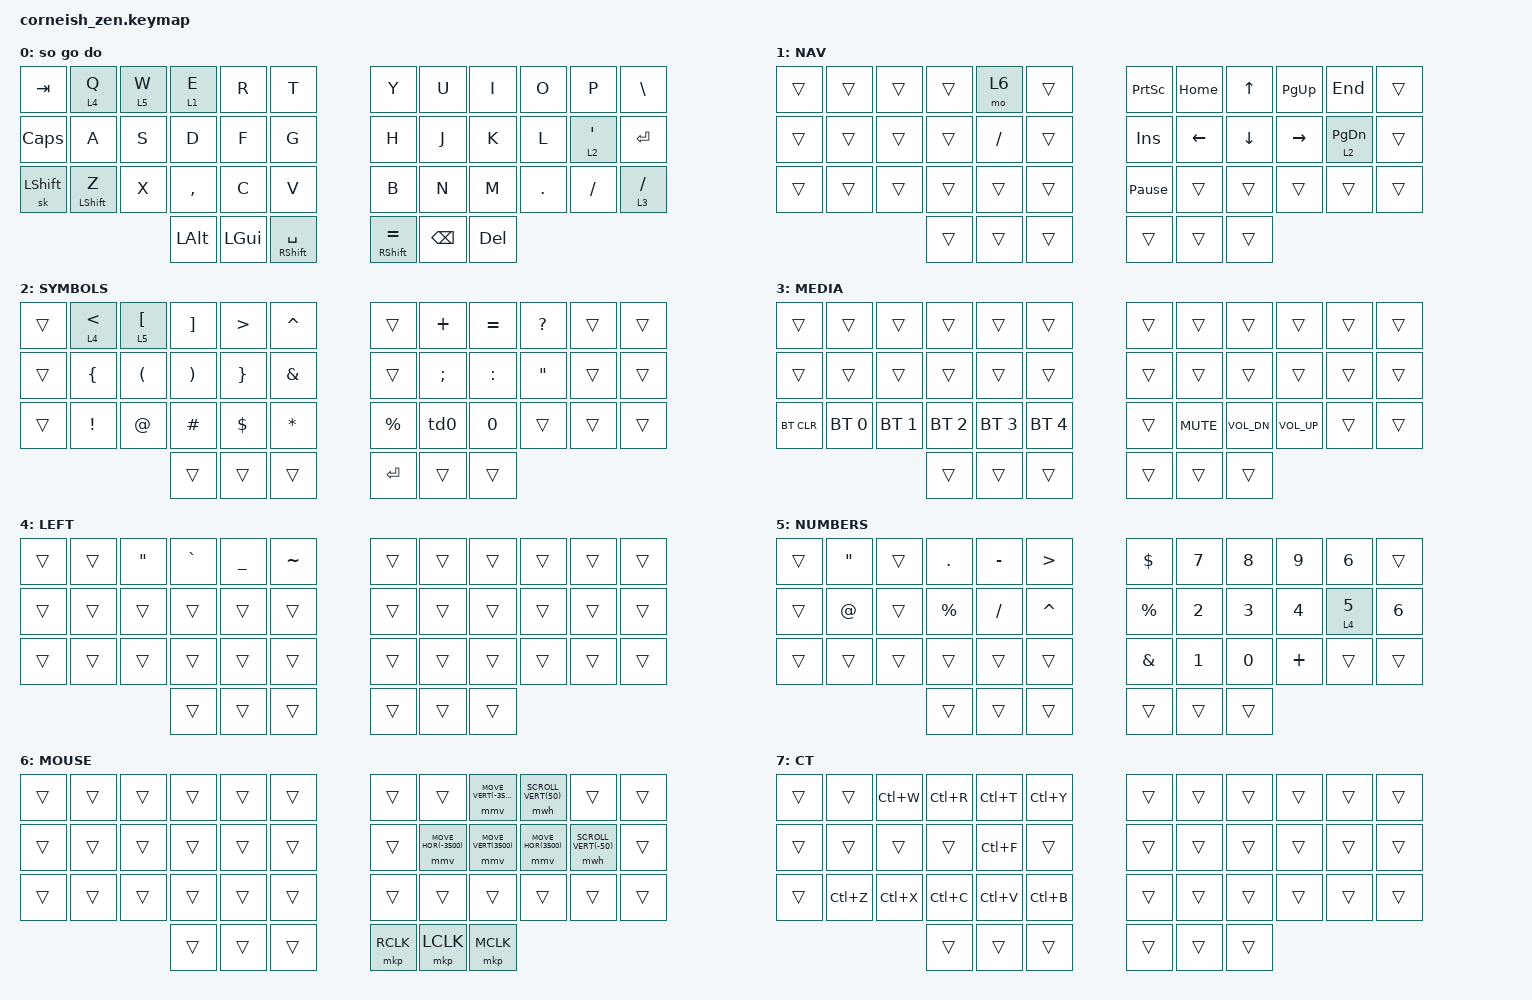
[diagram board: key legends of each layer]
#include <behaviors.dtsi>
#include <dt-bindings/zmk/keys.h>
#include <dt-bindings/zmk/bt.h>
#include <dt-bindings/zmk/mouse.h>

&lt {
    tapping-term-ms = <200>;
    flavor = "tap-preferred";
    retro-tap;

};

&mt {
    tapping-term-ms = <110>;
    flavor = "tap-preferred";
    retro-tap;
};

&mmv {
    time-to-max-speed-ms = <200>;
    acceleration-exponent=<1>;
};

&sk {
    quick-release;
};

&mwh {
    time-to-max-speed-ms = <200>;
    acceleration-exponent=<1>;
};


/ {
  chosen {
    zmk,matrix_transform = &default_transform;
    //zmk,matrix_transform = &five_column_transform;
  };
};

/ {
        behaviors {
            mt_bl: mod_tap_balanced {
                compatible = "zmk,behavior-hold-tap";
                label = "BALANCED_MODS";
                #binding-cells = <2>;
                tapping-term-ms = <150>;
                flavor = "balanced";
                bindings = <&kp>, <&kp>;
                // retro-tap;
            };
            
            lt_tp: layer_tap_tap_preferred {
                compatible = "zmk,behavior-hold-tap";
                label = "TAP_PREFERRED_MODS";
                #binding-cells = <2>;
                tapping-term-ms = <150>;
                flavor = "tap-preferred";
                bindings = <&mo>, <&kp>;
                retro-tap;
            };
            
            td0: tap_dance_0 {
                compatible = "zmk,behavior-tap-dance";
                label = "TAP_DANCE_0";
                #binding-cells = <0>;
                tapping-term-ms = <250>;
                // bindings = <&kp N1>, <&kp N2>, <&kp N3>, <&kp N4>, <&kp N5>, <&kp N6>, <&kp N7>, <&kp N8>, <&kp N9>;
                bindings = <&kp N1>, <&kp N2>;

            };
            td1: tap_dance_1 {
                compatible = "zmk,behavior-tap-dance";
                label = "TAP_DANCE_1";
                #binding-cells = <0>;
                tapping-term-ms = <250>;
                bindings = <&kp LSHFT>, <&mo 7>;
            };
        };
        combos {
            compatible = "zmk,combos";
            combo_q {
                timeout-ms = <50>;
                key-positions = <22 23>;
                bindings = <&kp QUESTION>;
            };
            combo_esc {
                timeout-ms = <50>;
                key-positions = <0 1>;
                bindings = <&kp ESC>;
            };
            combo_rarrow {
                timeout-ms = <50>;
                key-positions = <20 40>;
                bindings = <&mo 1>;
                slow-release;
            };
            combo_rmouse {
                timeout-ms = <50>;
                key-positions = <18 22>;
                bindings = <&mo 6>;
                slow-release;
            };
        };
        keymap {

        
                compatible = "zmk,keymap";

                default {
                    label = "so go do";
                    bindings = <
         &kp TAB        &lt 4 Q      &lt 5 W     &lt 1 E     &kp R            &kp T              &kp Y     &kp U    &kp I       &kp O       &kp P             &kp BSLH
         &kp CAPS      &kp A        &kp S       &kp D       &kp F            &kp G              &kp H     &kp J    &kp K       &kp L       &lt_tp 2 SQT      &kp ENTER
         &sk LSHFT	&mt LSHFT Z &kp X	&kp COMMA	&kp C	&kp V	&kp B	&kp N	&kp M	&kp DOT 	&kp SLASH	&lt 3 SLASH
                                            &kp LALT  &kp LGUI  &mt_bl RSHFT SPACE               &mt_bl RSHFT EQUAL   &kp BSPC  &kp DEL                   
                    >;
                };

                navigation {
                    label = "NAV";
                    bindings = <
         &trans  &trans  &trans  &trans      &mo 6  &trans          &kp PRINTSCREEN  &kp HOME    &kp UP  &kp PG_UP    &kp END  &trans
         &trans  &trans  &trans  &trans  &kp SLASH  &trans               &kp INS  &kp LEFT  &kp DOWN  &kp RIGHT  &lt_tp 2 PG_DN  &trans
         &trans  &trans  &trans  &trans     &trans  &trans          &kp PAUSE_BREAK    &trans    &trans     &trans     &trans  &trans
                                 &trans     &trans  &trans                   &trans    &trans    &trans
                    >;
                };

                symbol {
                    label = "SYMBOLS";
                    bindings = <
         &trans  &lt 4 LT  &lt 5 LEFT_BRACKET   &kp RBKT    &kp GT      &kp CARET            &trans    &kp PLUS   &kp EQUAL  &kp QUESTION  &trans  &trans
         &trans  &kp LBRC            &kp LPAR   &kp RPAR  &kp RBRC   &kp AMPERSAND            &trans      &kp SEMI     &kp COLON  &kp DQT  &trans  &trans
         &trans  &kp EXCL              &kp AT  &kp POUND  &kp DLLR  &kp ASTERISK            &kp PERCENT  &td0  &kp NUMBER_0   &trans  &trans  &trans
                                                  &trans    &trans         &trans          &kp ENTER    &trans &trans
                    >;
                };

                media {
                    label = "MEDIA";
                    bindings = <
             &trans        &trans        &trans        &trans        &trans        &trans          &trans      &trans        &trans        &trans  &trans  &trans
             &trans        &trans        &trans        &trans        &trans        &trans          &trans      &trans        &trans        &trans  &trans  &trans
         &bt BT_CLR  &bt BT_SEL 0  &bt BT_SEL 1  &bt BT_SEL 2  &bt BT_SEL 3  &bt BT_SEL 4          &trans  &kp C_MUTE  &kp C_VOL_DN  &kp C_VOL_UP  &trans  &trans
                                                       &trans        &trans        &trans          &trans      &trans        &trans
                    >;
                };
                left {
                    label = "LEFT";
                    bindings = <
         &trans  &trans  &kp DQT  &kp GRAVE  &kp UNDER  &kp TILDE          &trans  &trans  &trans  &trans  &trans  &trans
         &trans  &trans   &trans     &trans     &trans     &trans          &trans  &trans  &trans  &trans  &trans  &trans
         &trans  &trans   &trans     &trans     &trans     &trans          &trans  &trans  &trans  &trans  &trans  &trans
                                     &trans     &trans     &trans          &trans  &trans  &trans
                    >;
                };
                number {
                    label = "NUMBERS";
                    bindings = <
         &trans  &kp DQT  &trans  &kp DOT  &kp MINUS   &kp GT           &kp DOLLAR  &kp N7  &kp N8    &kp N9    &kp N6  &trans
         &trans   &kp AT  &trans  &kp PERCENT  &kp SLASH  &kp CARET          &kp PERCENT  &kp N2  &kp N3    &kp N4  &lt 4 N5  &kp N6
         &trans   &trans  &trans  &trans     &trans     &trans             &kp AMPS  &kp N1  &kp N0  &kp PLUS    &trans  &trans
                                  &trans     &trans     &trans               &trans  &trans  &trans
                    >;
                };
                mouse {
                    label = "MOUSE";
                    bindings = <
         &trans  &trans  &trans  &trans  &trans  &trans          &trans  &trans  &mmv MOVE_VERT(-3500) &mwh SCROLL_VERT(50)  &trans  &trans
         &trans  &trans  &trans  &trans  &trans  &trans          &trans  &mmv MOVE_HOR(-3500)  &mmv MOVE_VERT(3500)   &mmv MOVE_HOR(3500)  &mwh SCROLL_VERT(-50)  &trans
         &trans  &trans  &trans  &trans  &trans  &trans          &trans  &trans  &trans  &trans  &trans  &trans
                                 &trans  &trans  &trans          &mkp RCLK  &mkp LCLK  &mkp MCLK
                    >;
                };
                lctrlqwerty {
                    label = "CT";
                    bindings = <
         &trans  &trans   &kp LC(W)     &kp LC(R)     &kp LC(T)     &kp LC(Y)          &trans  &trans  &trans  &trans  &trans  &trans
         &trans  &trans   &trans     &trans     &kp LC(F)     &trans          &trans  &trans  &trans  &trans  &trans  &trans
         &trans  &kp LC(Z)   &kp LC(X)     &kp LC(C)     &kp LC(V)     &kp LC(B)          &trans  &trans  &trans  &trans  &trans  &trans
                                     &trans     &trans     &trans          &trans  &trans  &trans
                    >;
                };
                
        };
};
